# CH32V103xx register map
Vendor: WCH Ltd.; File version: 1.1
Registers are 32-bit, read-write, reset 0x0 unless marked. A register's access mark holds for its fields unless they carry their own. Offsets are from the block's base; [hi:lo] are bit positions.

## SPI1 — Serial peripheral interface
Base 0x40013000
Same registers: SPI2 0x40003800
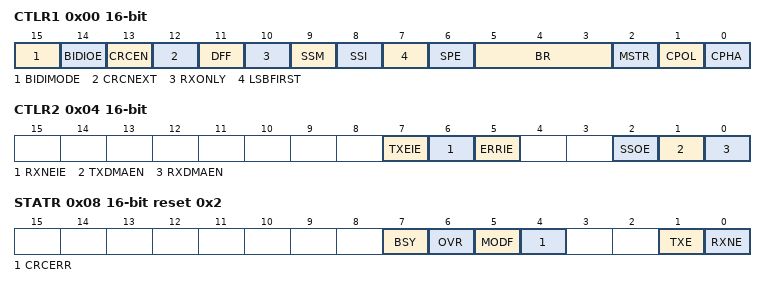
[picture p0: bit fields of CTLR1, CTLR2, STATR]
0x00 CTLR1 16-bit — control register 1
  [15] BIDIMODE — Bidirectional data mode enable
  [14] BIDIOE — Output enable in bidirectional mode
  [13] CRCEN — Hardware CRC calculation enable
  [12] CRCNEXT — CRC transfer next
  [11] DFF — Data frame format
  [10] RXONLY — Receive only
  [9] SSM — Software slave management
  [8] SSI — Internal slave select
  [7] LSBFIRST — Frame format
  [6] SPE — SPI enable
  [5:3] BR — Baud rate control
  [2] MSTR — Master selection
  [1] CPOL — Clock polarity
  [0] CPHA — Clock phase
0x04 CTLR2 16-bit — control register 2
  [7] TXEIE — Tx buffer empty interrupt enable
  [6] RXNEIE — RX buffer not empty interrupt enable
  [5] ERRIE — Error interrupt enable
  [2] SSOE — SS output enable
  [1] TXDMAEN — Tx buffer DMA enable
  [0] RXDMAEN — Rx buffer DMA enable
0x08 STATR 16-bit access per field reset 0x2 — status register
  [7] BSY ro — Busy flag
  [6] OVR ro — Overrun flag
  [5] MODF ro — Mode fault
  [4] CRCERR rw — CRC error flag
  [1] TXE ro — Transmit buffer empty
  [0] RXNE ro — Receive buffer not empty
0x0C DATAR 16-bit — data register
  [15:0] DATAR — Data register
0x10 CRCR 16-bit reset 0x7 — CRCR polynomial register
  [15:0] CRCPOLY — CRC polynomial register
0x14 RCRCR 16-bit ro — RX CRC register
  [15:0] RxCRC
0x18 TCRCR 16-bit ro — TX CRC register
  [15:0] TxCRC
0x24 HSCR 16-bit wo — High speed control register
  [0] HSRXEN — High speed read mode enable bit

## USART1 — Universal synchronous asynchronous receiver transmitter
Base 0x40013800
Same registers: USART2 0x40004400, USART3 0x40004800
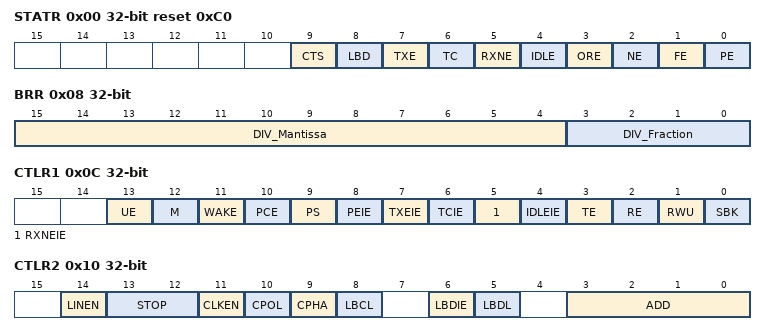
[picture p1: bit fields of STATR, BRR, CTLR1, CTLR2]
0x00 STATR reset 0xC0 — Status register
  [9] CTS — CTS flag
  [8] LBD — LIN break detection flag
  [7] TXE ro — Transmit data register empty
  [6] TC — Transmission complete
  [5] RXNE — Read data register not empty
  [4] IDLE ro — IDLE line detected
  [3] ORE ro — Overrun error
  [2] NE ro — Noise error flag
  [1] FE ro — Framing error
  [0] PE ro — Parity error
0x04 DATAR — Data register
  [8:0] DR — Data value
0x08 BRR — Baud rate register
  [15:4] DIV_Mantissa — mantissa of USARTDIV
  [3:0] DIV_Fraction — fraction of USARTDIV
0x0C CTLR1 — Control register 1
  [13] UE — USART enable
  [12] M — Word length
  [11] WAKE — Wakeup method
  [10] PCE — Parity control enable
  [9] PS — Parity selection
  [8] PEIE — PE interrupt enable
  [7] TXEIE — TXE interrupt enable
  [6] TCIE — Transmission complete interrupt enable
  [5] RXNEIE — RXNE interrupt enable
  [4] IDLEIE — IDLE interrupt enable
  [3] TE — Transmitter enable
  [2] RE — Receiver enable
  [1] RWU — Receiver wakeup
  [0] SBK — Send break
0x10 CTLR2 — Control register 2
  [14] LINEN — LIN mode enable
  [13:12] STOP — STOP bits
  [11] CLKEN — Clock enable
  [10] CPOL — Clock polarity
  [9] CPHA — Clock phase
  [8] LBCL — Last bit clock pulse
  [6] LBDIE — LIN break detection interrupt enable
  [5] LBDL — lin break detection length
  [3:0] ADD — Address of the USART node
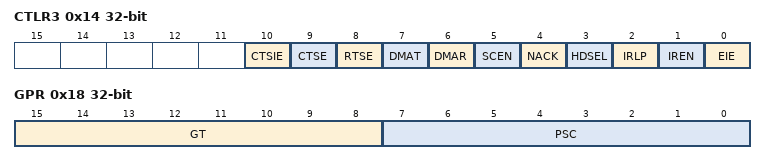
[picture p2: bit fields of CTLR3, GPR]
0x14 CTLR3 — Control register 3
  [10] CTSIE — CTS interrupt enable
  [9] CTSE — CTS enable
  [8] RTSE — RTS enable
  [7] DMAT — DMA enable transmitter
  [6] DMAR — DMA enable receiver
  [5] SCEN — Smartcard mode enable
  [4] NACK — Smartcard NACK enable
  [3] HDSEL — Half-duplex selection
  [2] IRLP — IrDA low-power
  [1] IREN — IrDA mode enable
  [0] EIE — Error interrupt enable
0x18 GPR — Guard time and prescaler register
  [15:8] GT — Guard time value
  [7:0] PSC — Prescaler value

## DAC1 — Digital to analog converter
Base 0x40007400
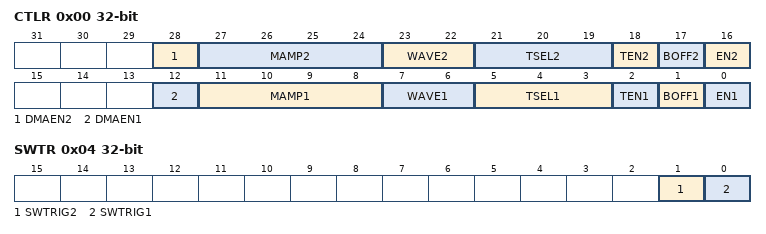
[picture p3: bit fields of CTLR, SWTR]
0x00 CTLR — Control register (DAC_CTLR)
  [28] DMAEN2 — DAC channel2 DMA enable
  [27:24] MAMP2 — DAC channel2 mask/amplitude selector
  [23:22] WAVE2 — DAC channel2 noise/triangle wave generation enable
  [21:19] TSEL2 — DAC channel2 trigger selection
  [18] TEN2 — DAC channel2 trigger enable
  [17] BOFF2 — DAC channel2 output buffer disable
  [16] EN2 — DAC channel2 enable
  [12] DMAEN1 — DAC channel1 DMA enable
  [11:8] MAMP1 — DAC channel1 mask/amplitude selector
  [7:6] WAVE1 — DAC channel1 noise/triangle wave generation enable
  [5:3] TSEL1 — DAC channel1 trigger selection
  [2] TEN1 — DAC channel1 trigger enable
  [1] BOFF1 — DAC channel1 output buffer disable
  [0] EN1 — DAC channel1 enable
0x04 SWTR wo — DAC software trigger register (DAC_SWTR)
  [1] SWTRIG2 — DAC channel2 software trigger
  [0] SWTRIG1 — DAC channel1 software trigger
0x08 R12BDHR1 — DAC channel1 12-bit right-aligned data holding register(DAC_R12BDHR1)
  [11:0] DACC1DHR — DAC channel1 12-bit right-aligned data
0x0C L12BDHR1 — DAC channel1 12-bit left aligned data holding register (DAC_L12BDHR1)
  [15:4] DACC1DHR — DAC channel1 12-bit left-aligned data
0x14 R12BDHR2 — DAC channel2 12-bit right aligned data holding register (DAC_R12BDHR2)
  [11:0] DACC2DHR — DAC channel2 12-bit right-aligned data
0x18 L12BDHR2 — DAC channel2 12-bit left aligned data holding register (DAC_L12BDHR2)
  [15:4] DACC2DHR — DAC channel2 12-bit left-aligned data
0x2C DOR1 ro — DAC channel1 data output register (DAC_DOR1)
  [11:0] DACC1DOR — DAC channel1 data output
0x30 DOR2 ro — DAC channel2 data output register (DAC_DOR2)
  [11:0] DACC2DOR — DAC channel2 data output
